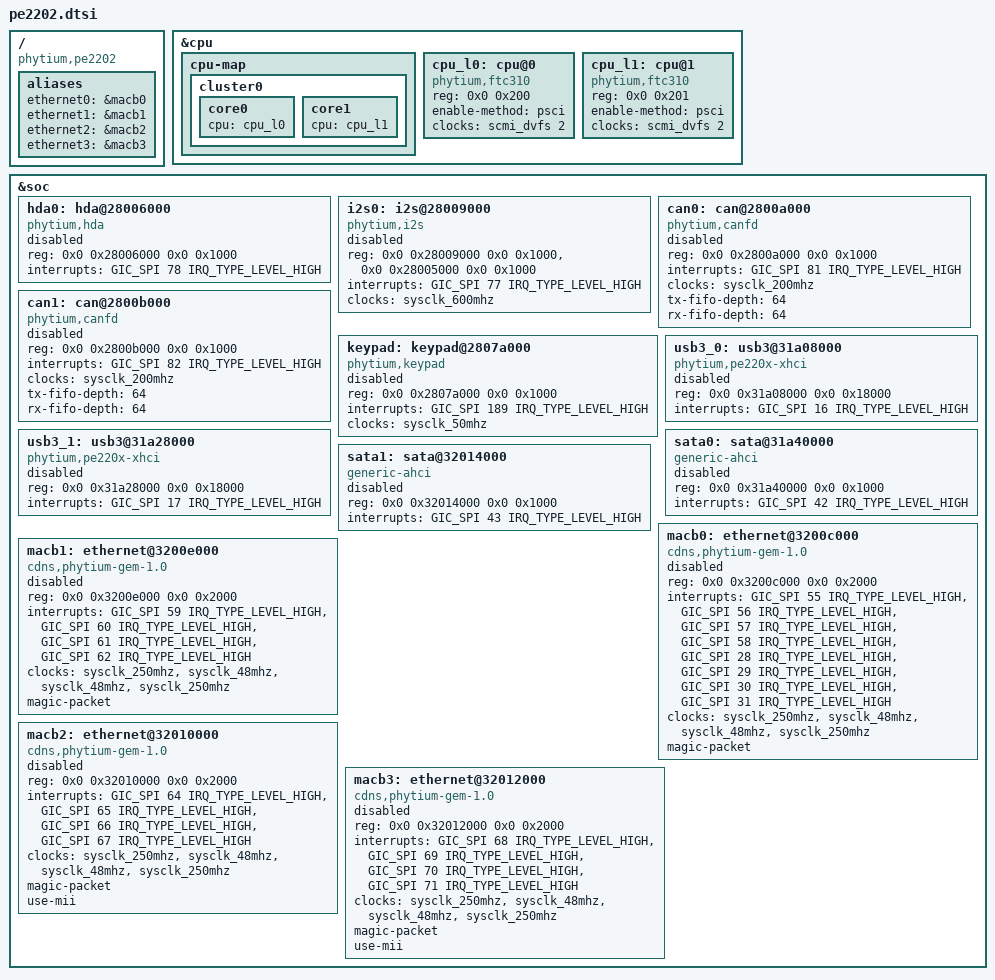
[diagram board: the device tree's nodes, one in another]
// SPDX-License-Identifier: GPL-2.0
/*
 * dts file for Phytium Pe2202 SoC
 *
 * Copyright (c) 2022-2023 Phytium Technology Co., Ltd.
 */

#include "pe220x.dtsi"

/ {
	compatible = "phytium,pe2202";

	aliases {
		ethernet0 = &macb0;
		ethernet1 = &macb1;
		ethernet2 = &macb2;
		ethernet3 = &macb3;
	};
};

&cpu {
	cpu-map {
		cluster0 {
			core0 {
				cpu = <&cpu_l0>;
			};

			core1 {
				cpu = <&cpu_l1>;
			};
		};
	};

	cpu_l0: cpu@0 {
		device_type = "cpu";
		compatible = "phytium,ftc310", "arm,armv8";
		reg = <0x0 0x200>;
		enable-method = "psci";
		clocks = <&scmi_dvfs 2>;
	};

	cpu_l1: cpu@1 {
		device_type = "cpu";
		compatible = "phytium,ftc310", "arm,armv8";
		reg = <0x0 0x201>;
		enable-method = "psci";
		clocks = <&scmi_dvfs 2>;
	};
};

&soc {
	hda0: hda@28006000 {
		compatible = "phytium,hda";
		reg = <0x0 0x28006000 0x0 0x1000>;
		interrupts = <GIC_SPI 78 IRQ_TYPE_LEVEL_HIGH>;
		status = "disabled";
	};

	i2s0: i2s@28009000 {
		compatible = "phytium,i2s";
		reg = <0x0 0x28009000 0x0 0x1000>,
			  <0x0 0x28005000 0x0 0x1000>;
		interrupts = <GIC_SPI 77 IRQ_TYPE_LEVEL_HIGH>;
		clocks = <&sysclk_600mhz>;
		clock-names = "i2s_clk";
		status = "disabled";
	};

	can0: can@2800a000 {
		compatible = "phytium,canfd";
		reg = <0x0 0x2800a000 0x0 0x1000>;
		interrupts = <GIC_SPI 81 IRQ_TYPE_LEVEL_HIGH>;
		clocks = <&sysclk_200mhz>;
		clock-names = "can_clk";
		tx-fifo-depth = <64>;
		rx-fifo-depth = <64>;
		status = "disabled";
	};

	can1: can@2800b000 {
		compatible = "phytium,canfd";
		reg = <0x0 0x2800b000 0x0 0x1000>;
		interrupts = <GIC_SPI 82 IRQ_TYPE_LEVEL_HIGH>;
		clocks = <&sysclk_200mhz>;
		clock-names = "can_clk";
		tx-fifo-depth = <64>;
		rx-fifo-depth = <64>;
		status = "disabled";
	};

	keypad: keypad@2807a000 {
		compatible = "phytium,keypad";
		reg = <0x0 0x2807a000 0x0 0x1000>;
		interrupts = <GIC_SPI 189 IRQ_TYPE_LEVEL_HIGH>;
		clocks = <&sysclk_50mhz>;
		status = "disabled";
	};

	usb3_0: usb3@31a08000 {
		compatible = "phytium,pe220x-xhci";
		reg = <0x0 0x31a08000 0x0 0x18000>;
		interrupts = <GIC_SPI 16 IRQ_TYPE_LEVEL_HIGH>;
		status = "disabled";
	};

	usb3_1: usb3@31a28000 {
		compatible = "phytium,pe220x-xhci";
		reg = <0x0 0x31a28000 0x0 0x18000>;
		interrupts = <GIC_SPI 17 IRQ_TYPE_LEVEL_HIGH>;
		status = "disabled";
	};

	sata0: sata@31a40000 {
		compatible = "generic-ahci";
		reg = <0x0 0x31a40000 0x0 0x1000>;
		interrupts = <GIC_SPI 42 IRQ_TYPE_LEVEL_HIGH>;
		status = "disabled";
	};

	sata1: sata@32014000 {
		compatible = "generic-ahci";
		reg = <0x0 0x32014000 0x0 0x1000>;
		interrupts = <GIC_SPI 43 IRQ_TYPE_LEVEL_HIGH>;
		status = "disabled";
	};

	macb0: ethernet@3200c000 {
		compatible = "cdns,phytium-gem-1.0";
		reg = <0x0 0x3200c000 0x0 0x2000>;
		interrupts = <GIC_SPI 55 IRQ_TYPE_LEVEL_HIGH>,
				 <GIC_SPI 56 IRQ_TYPE_LEVEL_HIGH>,
				 <GIC_SPI 57 IRQ_TYPE_LEVEL_HIGH>,
				 <GIC_SPI 58 IRQ_TYPE_LEVEL_HIGH>,
				 <GIC_SPI 28 IRQ_TYPE_LEVEL_HIGH>,
				 <GIC_SPI 29 IRQ_TYPE_LEVEL_HIGH>,
				 <GIC_SPI 30 IRQ_TYPE_LEVEL_HIGH>,
				 <GIC_SPI 31 IRQ_TYPE_LEVEL_HIGH>;
		clock-names = "pclk", "hclk", "tx_clk", "tsu_clk";
		clocks = <&sysclk_250mhz>, <&sysclk_48mhz>, <&sysclk_48mhz>, <&sysclk_250mhz>;
		magic-packet;
		status = "disabled";
	};

	macb1: ethernet@3200e000 {
		compatible = "cdns,phytium-gem-1.0";
		reg = <0x0 0x3200e000 0x0 0x2000>;
		interrupts = <GIC_SPI 59 IRQ_TYPE_LEVEL_HIGH>,
				 <GIC_SPI 60 IRQ_TYPE_LEVEL_HIGH>,
				 <GIC_SPI 61 IRQ_TYPE_LEVEL_HIGH>,
				 <GIC_SPI 62 IRQ_TYPE_LEVEL_HIGH>;
		clock-names = "pclk", "hclk", "tx_clk", "tsu_clk";
		clocks = <&sysclk_250mhz>, <&sysclk_48mhz>, <&sysclk_48mhz>, <&sysclk_250mhz>;
		magic-packet;
		status = "disabled";
	};

	macb2: ethernet@32010000 {
		compatible = "cdns,phytium-gem-1.0";
		reg = <0x0 0x32010000 0x0 0x2000>;
		interrupts = <GIC_SPI 64 IRQ_TYPE_LEVEL_HIGH>,
				 <GIC_SPI 65 IRQ_TYPE_LEVEL_HIGH>,
				 <GIC_SPI 66 IRQ_TYPE_LEVEL_HIGH>,
				 <GIC_SPI 67 IRQ_TYPE_LEVEL_HIGH>;
		clock-names = "pclk", "hclk", "tx_clk", "tsu_clk";
		clocks = <&sysclk_250mhz>, <&sysclk_48mhz>, <&sysclk_48mhz>, <&sysclk_250mhz>;
		magic-packet;
		use-mii;
		status = "disabled";
	};

	macb3: ethernet@32012000 {
		compatible = "cdns,phytium-gem-1.0";
		reg = <0x0 0x32012000 0x0 0x2000>;
		interrupts = <GIC_SPI 68 IRQ_TYPE_LEVEL_HIGH>,
				 <GIC_SPI 69 IRQ_TYPE_LEVEL_HIGH>,
				 <GIC_SPI 70 IRQ_TYPE_LEVEL_HIGH>,
				 <GIC_SPI 71 IRQ_TYPE_LEVEL_HIGH>;
		clock-names = "pclk", "hclk", "tx_clk", "tsu_clk";
		clocks = <&sysclk_250mhz>, <&sysclk_48mhz>, <&sysclk_48mhz>, <&sysclk_250mhz>;
		magic-packet;
		use-mii;
		status = "disabled";
	};
};
